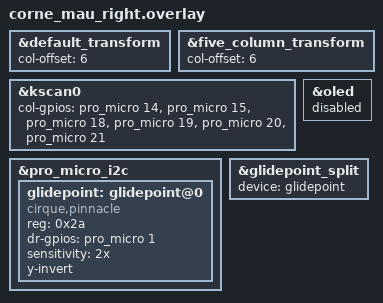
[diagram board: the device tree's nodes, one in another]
/*
 * Copyright (c) 2020 Pete Johanson
 *
 * SPDX-License-Identifier: MIT
 */

#include "corne_mau.dtsi"

&default_transform {
    col-offset = <6>;
};

&five_column_transform {
    col-offset = <6>;
};

&kscan0 {
    col-gpios
        = <&pro_micro 14 GPIO_ACTIVE_HIGH>
        , <&pro_micro 15 GPIO_ACTIVE_HIGH>
        , <&pro_micro 18 GPIO_ACTIVE_HIGH>
        , <&pro_micro 19 GPIO_ACTIVE_HIGH>
        , <&pro_micro 20 GPIO_ACTIVE_HIGH>
        , <&pro_micro 21 GPIO_ACTIVE_HIGH>
        ;
};

// Disable unused OLED on right half
&oled {
    status = "disabled";
};

// This is the first step to configure the pointing device
&pro_micro_i2c {
    glidepoint: glidepoint@0 {
        compatible = "cirque,pinnacle";
        reg = <0x2a>;
        status = "okay";
        dr-gpios = <&pro_micro 1 (GPIO_ACTIVE_HIGH)>;
        sensitivity = "2x";
        y-invert;
    };
};

// This is the third step to configure the pointer
&glidepoint_split {
    status = "okay";
    device = <&glidepoint>;
};
